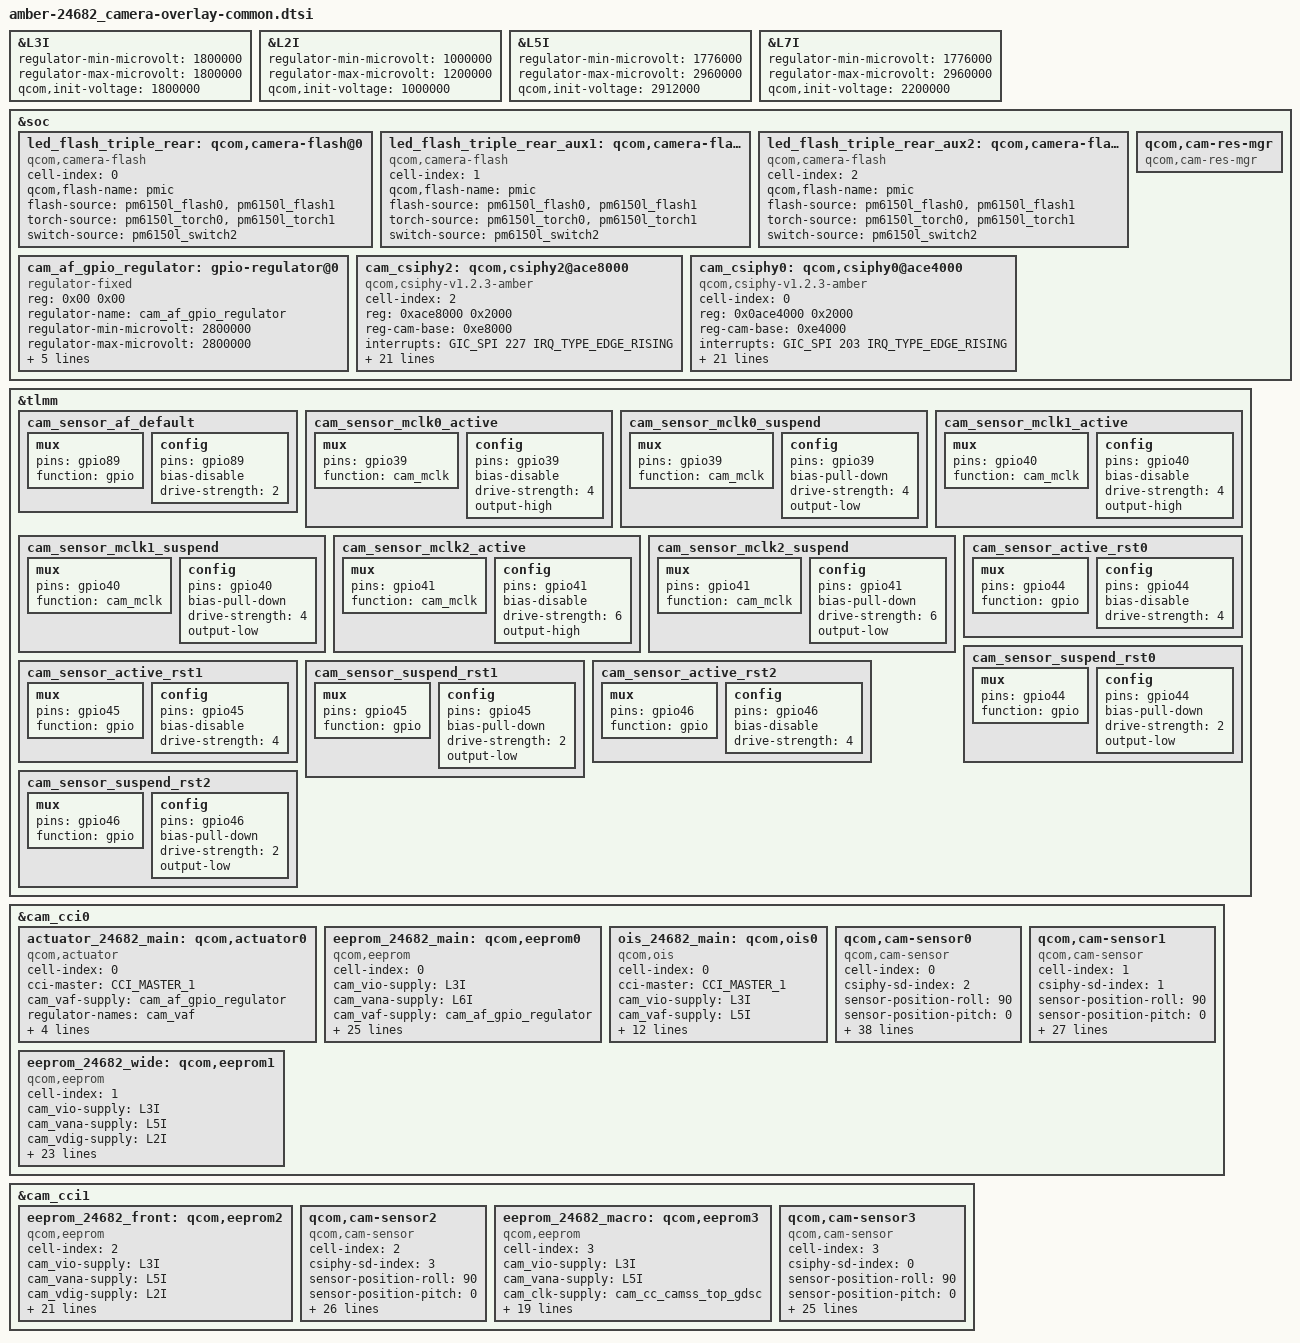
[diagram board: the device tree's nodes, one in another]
#include <dt-bindings/clock/qcom,camcc-parrot.h>
#include <dt-bindings/msm-camera.h>

&L3I {
     regulator-min-microvolt = <1800000>;
     regulator-max-microvolt = <1800000>;
     qcom,init-voltage = <1800000>;
	};

&L2I {
     regulator-min-microvolt = <1000000>;
     regulator-max-microvolt = <1200000>;
     qcom,init-voltage = <1000000>;
	};

&L5I {
	regulator-min-microvolt = <1776000>;
	regulator-max-microvolt = <2960000>;
	qcom,init-voltage = <2912000>;
	};

&L7I {
	regulator-min-microvolt = <1776000>;
	regulator-max-microvolt = <2960000>;
	qcom,init-voltage = <2200000>;
	};

&soc {
	led_flash_triple_rear: qcom,camera-flash@0 {
		cell-index = <0>;
		compatible = "qcom,camera-flash";
		qcom,flash-name = "pmic";
		flash-source = <&pm6150l_flash0 &pm6150l_flash1>;
		torch-source = <&pm6150l_torch0 &pm6150l_torch1>;
		switch-source = <&pm6150l_switch2>;
		status = "ok";
	};

	led_flash_triple_rear_aux1: qcom,camera-flash@1 {
		cell-index = <1>;
		compatible = "qcom,camera-flash";
		qcom,flash-name = "pmic";
		flash-source = <&pm6150l_flash0 &pm6150l_flash1>;
		torch-source = <&pm6150l_torch0 &pm6150l_torch1>;
		switch-source = <&pm6150l_switch2>;
		status = "ok";
	};

	led_flash_triple_rear_aux2: qcom,camera-flash@2 {
		cell-index = <2>;
		compatible = "qcom,camera-flash";
		qcom,flash-name = "pmic";
		flash-source = <&pm6150l_flash0 &pm6150l_flash1>;
		torch-source = <&pm6150l_torch0 &pm6150l_torch1>;
		switch-source = <&pm6150l_switch2>;
		status = "ok";
	};

	qcom,cam-res-mgr {
		compatible = "qcom,cam-res-mgr";
		status = "ok";
	};

	cam_af_gpio_regulator: gpio-regulator@0 {
		compatible = "regulator-fixed";
		reg = <0x00 0x00>;
		regulator-name = "cam_af_gpio_regulator";
		regulator-min-microvolt = <2800000>;
		regulator-max-microvolt = <2800000>;
		regulator-enable-ramp-delay = <135>;
		enable-active-high;
		gpio = <&tlmm 89 0>;
		pinctrl-names = "default";
		pinctrl-0 = <&cam_sensor_af_default>;
		vin-supply = <&BOB>;
	};

	cam_csiphy2: qcom,csiphy2@ace8000 {
		cell-index = <2>;
		compatible = "qcom,csiphy-v1.2.3-amber", "qcom,csiphy";
		reg = <0xace8000 0x2000>;
		reg-names = "csiphy";
		reg-cam-base = <0xe8000>;
		interrupt-names = "CSIPHY2";
		interrupts = <GIC_SPI 227 IRQ_TYPE_EDGE_RISING>;
		regulator-names = "camss", "csi-vdd-1p2", "csi-vdd-0p9";
		camss-supply = <&cam_cc_camss_top_gdsc>;
		csi-vdd-1p2-supply = <&L16B>;
		csi-vdd-0p9-supply = <&L5B>;
		rgltr-cntrl-support;
		rgltr-enable-sync = <1>;
		rgltr-min-voltage = <0 1140000 830000>;
		rgltr-max-voltage = <0 1260000 920000>;
		rgltr-load-current = <0 89000 159000>;
		shared-clks = <1 0 0 0>;
		clock-names = "cphy_rx_clk_src",
			"csiphy2_clk",
			"csi2phytimer_clk_src",
			"csi2phytimer_clk";
		clocks = <&camcc CAM_CC_CPHY_RX_CLK_SRC>,
			<&camcc CAM_CC_CSIPHY2_CLK>,
			<&camcc CAM_CC_CSI2PHYTIMER_CLK_SRC>,
			<&camcc CAM_CC_CSI2PHYTIMER_CLK>;
		src-clock-name = "csi2phytimer_clk_src";
		clock-cntl-level = "lowsvs", "svs", "svs_l1", "nominal";
		clock-rates =
			<300000000 0 300000000 0>,
			<400000000 0 300000000 0>,
			<400000000 0 300000000 0>,
			<400000000 0 300000000 0>;
		status = "ok";
	};

	cam_csiphy0: qcom,csiphy0@ace4000 {
		cell-index = <0>;
		compatible = "qcom,csiphy-v1.2.3-amber", "qcom,csiphy";
		reg = < 0x0ace4000 0x2000>;
		reg-names = "csiphy";
		reg-cam-base = <0xe4000>;
		interrupt-names = "CSIPHY0";
		interrupts = <GIC_SPI 203 IRQ_TYPE_EDGE_RISING>;
		regulator-names = "camss", "csi-vdd-1p2", "csi-vdd-0p9";
		camss-supply = <&cam_cc_camss_top_gdsc>;
		csi-vdd-1p2-supply = <&L16B>;
		csi-vdd-0p9-supply = <&L5B>;
		rgltr-cntrl-support;
		rgltr-enable-sync = <1>;
		rgltr-min-voltage = <0 1140000 830000>;
		rgltr-max-voltage = <0 1260000 920000>;
		rgltr-load-current = <0 89000 159000>;
		shared-clks = <1 0 0 0>;
		clock-names = "cphy_rx_clk_src",
			"csiphy0_clk",
			"csi0phytimer_clk_src",
			"csi0phytimer_clk";
		clocks = <&camcc CAM_CC_CPHY_RX_CLK_SRC>,
			<&camcc CAM_CC_CSIPHY0_CLK>,
			<&camcc CAM_CC_CSI0PHYTIMER_CLK_SRC>,
			<&camcc CAM_CC_CSI0PHYTIMER_CLK>;
		src-clock-name = "csi0phytimer_clk_src";
		clock-cntl-level = "lowsvs", "svs", "svs_l1", "nominal";
		clock-rates =
			<300000000 0 300000000 0>,
			<400000000 0 300000000 0>,
			<400000000 0 300000000 0>,
			<400000000 0 300000000 0>;
		status = "ok";
	};
};

&tlmm{
	cam_sensor_af_default: cam_sensor_af_default {
		mux {
			pins = "gpio89";
			function = "gpio";
		};

		config {
			pins = "gpio89";
			bias-disable; /* No PULL */
			drive-strength = <2>; /* 2 MA */
		};
	};

	cam_sensor_mclk0_active: cam_sensor_mclk0_active {
		/* MCLK0 */
		mux {
			pins = "gpio39";
			function = "cam_mclk";
		};

		config {
			pins = "gpio39";
			bias-disable; /* No PULL */
			drive-strength = <4>; /* 6 MA */
			output-high;
		};
	};

	cam_sensor_mclk0_suspend: cam_sensor_mclk0_suspend {
		/* MCLK0 */
		mux {
			pins = "gpio39";
			function = "cam_mclk";
		};

		config {
			pins = "gpio39";
			bias-pull-down; /* PULL DOWN */
			drive-strength = <4>; /* 6 MA */
			output-low;
		};
	};

	cam_sensor_mclk1_active: cam_sensor_mclk1_active {
		/* MCLK1 */
		mux {
			pins = "gpio40";
			function = "cam_mclk";
		};

		config {
			pins = "gpio40";
			bias-disable; /* No PULL */
			drive-strength = <4>; /* 6 MA */
			output-high;
		};
	};

	cam_sensor_mclk1_suspend: cam_sensor_mclk1_suspend {
		/* MCLK1 */
		mux {
			pins = "gpio40";
			function = "cam_mclk";
		};

		config {
			pins = "gpio40";
			bias-pull-down; /* PULL DOWN */
			drive-strength = <4>; /* 6 MA */
			output-low;
		};
	};

	cam_sensor_mclk2_active: cam_sensor_mclk2_active {
		/* MCLK2 */
		mux {
			pins = "gpio41";
			function = "cam_mclk";
		};

		config {
			pins = "gpio41";
			bias-disable; /* No PULL */
			drive-strength = <6>; /* 6 MA */
			output-high;
		};
	};

	cam_sensor_mclk2_suspend: cam_sensor_mclk2_suspend {
		/* MCLK2 */
		mux {
			pins = "gpio41";
			function = "cam_mclk";
		};

		config {
			pins = "gpio41";
			bias-pull-down; /* PULL DOWN */
			drive-strength = <6>; /* 6 MA */
			output-low;
		};
	};

	cam_sensor_active_rst0: cam_sensor_active_rst0 {
		/* RESET REAR */
		mux {
			pins = "gpio44";
			function = "gpio";
		};

		config {
			pins = "gpio44";
			bias-disable; /* No PULL */
			drive-strength = <4>; /* 2 MA */
		};
	};

	cam_sensor_suspend_rst0: cam_sensor_suspend_rst0 {
		/* RESET REAR */
		mux {
			pins = "gpio44";
			function = "gpio";
		};

		config {
			pins = "gpio44";
			bias-pull-down; /* PULL DOWN */
			drive-strength = <2>; /* 2 MA */
			output-low;
		};
	};

	cam_sensor_active_rst1: cam_sensor_active_rst1 {
		/* RESET REARAUX */
		mux {
			pins = "gpio45";
			function = "gpio";
		};

		config {
			pins = "gpio45";
			bias-disable; /* No PULL */
			drive-strength = <4>; /* 2 MA */
		};
	};

	cam_sensor_suspend_rst1: cam_sensor_suspend_rst1 {
		/* RESET REARAUX */
		mux {
			pins = "gpio45";
			function = "gpio";
		};

		config {
			pins = "gpio45";
			bias-pull-down; /* PULL DOWN */
			drive-strength = <2>; /* 2 MA */
			output-low;
		};
	};

	cam_sensor_active_rst2: cam_sensor_active_rst2 {
		/* RESET 2 */
		mux {
			pins = "gpio46";
			function = "gpio";
		};

		config {
			pins = "gpio46";
			bias-disable; /* No PULL */
			drive-strength = <4>; /* 2 MA */
		};
	};

	cam_sensor_suspend_rst2: cam_sensor_suspend_rst2 {
		/* RESET 2 */
		mux {
			pins = "gpio46";
			function = "gpio";
		};

		config {
			pins = "gpio46";
			bias-pull-down; /* PULL DOWN */
			drive-strength = <2>; /* 2 MA */
			output-low;
		};
	};
};

&cam_cci0 {
	actuator_24682_main: qcom,actuator0 {
		cell-index = <0>;
		compatible = "qcom,actuator";
		cci-master = <CCI_MASTER_1>;
		cam_vaf-supply = <&cam_af_gpio_regulator>;
		regulator-names = "cam_vaf";
		rgltr-cntrl-support;
		rgltr-min-voltage = <2800000>;
		rgltr-max-voltage = <2800000>;
		rgltr-load-current = <103000>;
	};

	//GT24P128G-2CSLI-TR
	eeprom_24682_main: qcom,eeprom0 {
		cell-index = <0>;
		compatible = "qcom,eeprom";
		cam_vio-supply = <&L3I>;
		cam_vana-supply = <&L6I>;
		cam_vaf-supply = <&cam_af_gpio_regulator>;
		cam_vdig-supply = <&L1I>;
		cam_clk-supply = <&cam_cc_camss_top_gdsc>;
		regulator-names = "cam_vio", "cam_vana", "cam_vaf","cam_vdig", "cam_clk";
		rgltr-cntrl-support;
		rgltr-min-voltage = <1800000 2800000 2800000  1104000 0>;
		rgltr-max-voltage = <1800000 2800000 2800000  1104000 0>;
		rgltr-load-current = <300000 300000 300000  1200000 0>;
		gpio-no-mux = <0>;
		pinctrl-names = "cam_default", "cam_suspend";
		pinctrl-0 = <&cam_sensor_mclk1_active
				 &cam_sensor_active_rst1>;
		pinctrl-1 = <&cam_sensor_mclk1_suspend
				 &cam_sensor_suspend_rst1>;
		gpios = <&tlmm 40 0>,
			<&tlmm 45 0>;
		gpio-reset = <1>;
		gpio-req-tbl-num = <0 1>;
		gpio-req-tbl-flags = <1 0>;
		gpio-req-tbl-label = "CAMIF_MCLK1",
					"CAM_RESET1";
		cci-master = <CCI_MASTER_1>;
		clocks = <&camcc CAM_CC_MCLK1_CLK>;
		clock-names = "cam_clk";
		clock-cntl-level = "nominal";
		clock-rates = <19200000>;
		status = "ok";
	};

	ois_24682_main: qcom,ois0 {
		cell-index = <0>;
		compatible = "qcom,ois";
		cci-master = <CCI_MASTER_1>;
		cam_vio-supply = <&L3I>;
		cam_vaf-supply = <&L5I>;
		regulator-names = "cam_vio",  "cam_vaf";
		rgltr-cntrl-support;
		rgltr-min-voltage = <1800000 2800000>;
		rgltr-max-voltage = <1800000 2800000>;
		rgltr-load-current = <300000 300000>;
		ois_gyro,position=<3>;
		ois_gyro,type=<3>;
		ois,type=<0>;
		ois,name="dw9828c";
		ois_module,vendor=<1>;
		ois_actuator,vednor=<2>;
		ois,fw=<0>;
		status = "ok";
	};

	//IMX882
	qcom,cam-sensor0 {
		cell-index = <0>;
		compatible = "qcom,cam-sensor";
		csiphy-sd-index = <2>;
		sensor-position-roll = <90>;
		sensor-position-pitch = <0>;
		sensor-position-yaw = <180>;
		eeprom-src = <&eeprom_24682_main>;
		actuator-src = <&actuator_24682_main>;
		led-flash-src = <&led_flash_triple_rear>;
		//ois-src = <&ois_24682_main>;
		cam_vio-supply = <&L3I>;
		cam_vana-supply = <&L6I>;
		cam_vaf-supply = <&cam_af_gpio_regulator>;
		cam_vdig-supply = <&L1I>;
		cam_clk-supply = <&cam_cc_camss_top_gdsc>;
		regulator-names = "cam_vio", "cam_vana", "cam_vaf","cam_vdig", "cam_clk";
		rgltr-cntrl-support;
		rgltr-min-voltage = <1800000 2800000 2800000  1104000 0>;
		rgltr-max-voltage = <1800000 2800000 2800000  1104000 0>;
		rgltr-load-current = <300000 300000 300000  1200000 0>;
		gpio-no-mux = <0>;
		pinctrl-names = "cam_default", "cam_suspend";
		pinctrl-0 = <&cam_sensor_mclk1_active
				 &cam_sensor_active_rst1>;
		pinctrl-1 = <&cam_sensor_mclk1_suspend
				 &cam_sensor_suspend_rst1>;
		gpios = <&tlmm 40 0>,
			<&tlmm 45 0>;
		gpio-reset = <1>;
		gpio-req-tbl-num = <0 1>;
		gpio-req-tbl-flags = <1 0>;
		gpio-req-tbl-label = "CAMIF_MCLK1",
					"CAM_RESET1";
		cci-master = <CCI_MASTER_1>;
		clocks = <&camcc CAM_CC_MCLK1_CLK>;
		clock-names = "cam_clk";
		clock-cntl-level = "nominal";
		clock-rates = <19200000>;
		is_power_up_advance = <1>;
		enable_qsc_write_in_advance = <1>;
		qsc_reg_addr = <0x2210>;
		eeprom_slave_addr = <0xA0>;
		qsc_data_size = <3072>;
		write_qsc_addr = <0xC000>;
		status = "ok";
	};
	eeprom_24682_wide: qcom,eeprom1 {
		cell-index = <1>;
		compatible = "qcom,eeprom";
		cam_vio-supply = <&L3I>;
		cam_vana-supply = <&L5I>;
		cam_vdig-supply = <&L2I>;
		cam_clk-supply = <&cam_cc_camss_top_gdsc>;
		regulator-names = "cam_vio", "cam_vana","cam_vdig", "cam_clk";
		rgltr-cntrl-support;
		rgltr-min-voltage = <1800000 2800000 1200000 0>;
		rgltr-max-voltage = <1800000 2912000 1200000 0>;
		rgltr-load-current = <300000 300000 1200000 0>;
		gpio-no-mux = <0>;
		pinctrl-names = "cam_default", "cam_suspend";
		pinctrl-0 = <&cam_sensor_mclk0_active
				&cam_sensor_active_rst0>;
		pinctrl-1 = <&cam_sensor_mclk0_suspend
				&cam_sensor_suspend_rst0>;
		gpios = <&tlmm 39 0>,
			<&tlmm 44 0>;
		gpio-reset = <1>;
		gpio-req-tbl-num = <0 1>;
		gpio-req-tbl-flags = <1 0>;
		gpio-req-tbl-label = "CAMIF_MCLK0",
					"CAM_RESET0";
		cci-master = <CCI_MASTER_0>;
		clocks = <&camcc CAM_CC_MCLK0_CLK>;
		clock-names = "cam_clk";
		clock-cntl-level = "nominal";
		clock-rates = <24000000>;
		insensor-page-eeprom-support = <1>;
		oplus-eeprom-name = "sc820cs_wide";
		status = "ok";
	};
	//sc820cs
	qcom,cam-sensor1 {
		cell-index = <1>;
		compatible = "qcom,cam-sensor";
		csiphy-sd-index = <1>;
		sensor-position-roll = <90>;
		sensor-position-pitch = <0>;
		sensor-position-yaw = <180>;
		eeprom-src = <&eeprom_24682_wide>;
		led-flash-src = <&led_flash_triple_rear_aux2>;
		cam_vio-supply = <&L3I>;
		cam_vana-supply = <&L5I>;
		cam_vdig-supply = <&L2I>;
		cam_clk-supply = <&cam_cc_camss_top_gdsc>;
		regulator-names = "cam_vio", "cam_vana", "cam_vdig", "cam_clk";
		rgltr-cntrl-support;
		rgltr-min-voltage = <1800000 2800000 1200000 0>;
		rgltr-max-voltage = <1800000 2912000 1200000 0>;
		rgltr-load-current = <300000 300000 1200000 0>;
		gpio-no-mux = <0>;
		pinctrl-names = "cam_default", "cam_suspend";
		pinctrl-0 = <&cam_sensor_mclk0_active
				&cam_sensor_active_rst0>;
		pinctrl-1 = <&cam_sensor_mclk0_suspend
				&cam_sensor_suspend_rst0>;
		gpios = <&tlmm 39 0>,
			<&tlmm 44 0>;
		gpio-reset = <1>;
		gpio-req-tbl-num = <0 1>;
		gpio-req-tbl-flags = <1 0>;
		gpio-req-tbl-label = "CAMIF_MCLK0",
					"CAM_RESET0";
		cci-master = <CCI_MASTER_0>;
		clocks = <&camcc CAM_CC_MCLK0_CLK>;
		clock-names = "cam_clk";
		clock-cntl-level = "nominal";
		clock-rates = <24000000>;
		status = "ok";
	};
};

&cam_cci1 {

eeprom_24682_front: qcom,eeprom2 {
		cell-index = <2>;
		compatible = "qcom,eeprom";
		cam_vio-supply = <&L3I>;
		cam_vana-supply = <&L5I>;
		cam_vdig-supply = <&L2I>;
		cam_clk-supply = <&cam_cc_camss_top_gdsc>;
		regulator-names = "cam_vio", "cam_vana", "cam_vdig","cam_clk";
		rgltr-cntrl-support;
		rgltr-min-voltage = <1800000 2912000 1100000  0>;
		rgltr-max-voltage = <1800000 2912000 1200000  0>;
		rgltr-load-current = <300000 300000 1200000  0>;
		gpio-no-mux = <0>;
		pinctrl-names = "cam_default", "cam_suspend";
		pinctrl-0 = <&cam_sensor_mclk3_active
				&cam_sensor_active_rst3>;
		pinctrl-1 = <&cam_sensor_mclk3_suspend
				&cam_sensor_suspend_rst3>;
		gpios = <&tlmm 42 0>,
			<&tlmm 47 0>;
		gpio-reset = <1>;
		gpio-req-tbl-num = <0 1>;
		gpio-req-tbl-flags = <1 0>;
		gpio-req-tbl-label = "CAMIF_MCLK3",
					"CAM_RESET3";
		cci-master = <CCI_MASTER_1>;
		clocks = <&camcc CAM_CC_MCLK3_CLK>;
		clock-names = "cam_clk";
		clock-cntl-level = "nominal";
		clock-rates = <19200000>;
		status = "ok";
	};

    //imx615
    qcom,cam-sensor2 {
		cell-index = <2>;
		compatible = "qcom,cam-sensor";
		csiphy-sd-index = <3>;
		sensor-position-roll = <90>;
		sensor-position-pitch = <0>;
		sensor-position-yaw = <0>;
		eeprom-src = <&eeprom_24682_front>;
		//led-flash-src = <&led_flash_rear_tele>;
		cam_vio-supply = <&L3I>;
		cam_vana-supply = <&L5I>;
		cam_vdig-supply = <&L2I>; //gpio131
		cam_clk-supply = <&cam_cc_camss_top_gdsc>;
		regulator-names = "cam_vio", "cam_vana", "cam_vdig","cam_clk";
		rgltr-cntrl-support;
		rgltr-min-voltage = <1800000 2912000 1100000  0 >;
		rgltr-max-voltage = <1800000 2912000 1200000  0 >;
		rgltr-load-current = <300000 300000 1200000  0>;
		gpio-no-mux = <0>;
		pinctrl-names = "cam_default", "cam_suspend";
		pinctrl-0 = <&cam_sensor_mclk3_active
				 &cam_sensor_active_rst3>;
		pinctrl-1 = <&cam_sensor_mclk3_suspend
				 &cam_sensor_suspend_rst3>;
		gpios = <&tlmm 42 0>,
			<&tlmm 47 0>;
		gpio-reset = <1>;
		gpio-req-tbl-num = <0 1>;
		gpio-req-tbl-flags = <1 0>;
		gpio-req-tbl-label = "CAMIF_MCLK3",
					"CAM_RESET3";
		cci-master = <CCI_MASTER_1>;
		clocks = <&camcc CAM_CC_MCLK3_CLK>;
		clock-names = "cam_clk";
		clock-cntl-level = "nominal";
		clock-rates = <19200000>;
		status = "ok";
	};

//gc02m3_CN24C64PL
eeprom_24682_macro: qcom,eeprom3 {
		cell-index = <3>;
		compatible = "qcom,eeprom";
		cam_vio-supply = <&L3I>;
		cam_vana-supply = <&L5I>;
		cam_clk-supply = <&cam_cc_camss_top_gdsc>;
		regulator-names = "cam_vio", "cam_vana", "cam_clk";
		rgltr-cntrl-support;
		rgltr-min-voltage = <1800000 2800000 0>;
		rgltr-max-voltage = <1800000 2912000 0>;
		rgltr-load-current = <120000 300000 0>;
		gpio-no-mux = <0>;
		pinctrl-names = "cam_default", "cam_suspend";
		pinctrl-0 = <&cam_sensor_mclk2_active
				 &cam_sensor_active_rst2>;
		pinctrl-1 = <&cam_sensor_mclk2_suspend
				 &cam_sensor_suspend_rst2>;
		gpios = <&tlmm 41 0>,
			<&tlmm 46 0>;
		gpio-reset = <1>;
		gpio-req-tbl-num = <0 1>;
		gpio-req-tbl-flags = <1 0>;
		gpio-req-tbl-label = "CAMIF_MCLK2",
					"CAM_RESET2";
		cci-master = <CCI_MASTER_0>;
		clocks = <&camcc CAM_CC_MCLK2_CLK>;
		clock-names = "cam_clk";
		clock-cntl-level = "nominal";
		clock-rates = <19200000>;
		status = "ok";
	};
   //gc02m3
	qcom,cam-sensor3 {
		cell-index = <3>;
		compatible = "qcom,cam-sensor";
		csiphy-sd-index = <0>;
		sensor-position-roll = <90>;
		sensor-position-pitch = <0>;
		sensor-position-yaw = <0>;
		eeprom-src = <&eeprom_24682_macro>;
		led-flash-src = <&led_flash_triple_rear_aux1>;
		cam_vio-supply = <&L3I>;
		cam_vana-supply = <&L5I>;
		cam_clk-supply = <&cam_cc_camss_top_gdsc>;
		regulator-names = "cam_vio", "cam_vana", "cam_clk";
		rgltr-cntrl-support;
		rgltr-min-voltage = <1800000 2800000 0>;
		rgltr-max-voltage = <1800000 2912000 0>;
		rgltr-load-current = <120000 300000 0>;
		gpio-no-mux = <0>;
		pinctrl-names = "cam_default", "cam_suspend";
		pinctrl-0 = <&cam_sensor_mclk2_active
				 &cam_sensor_active_rst2>;
		pinctrl-1 = <&cam_sensor_mclk2_suspend
				 &cam_sensor_suspend_rst2>;
		gpios = <&tlmm 41 0>,
			<&tlmm 46 0>;
		gpio-reset = <1>;
		gpio-req-tbl-num = <0 1>;
		gpio-req-tbl-flags = <1 0>;
		gpio-req-tbl-label = "CAMIF_MCLK2",
					"CAM_RESET2";
		cci-master = <CCI_MASTER_0>;
		clocks = <&camcc CAM_CC_MCLK2_CLK>;
		clock-names = "cam_clk";
		clock-cntl-level = "nominal";
		clock-rates = <19200000>;
		status = "ok";
	};
};

